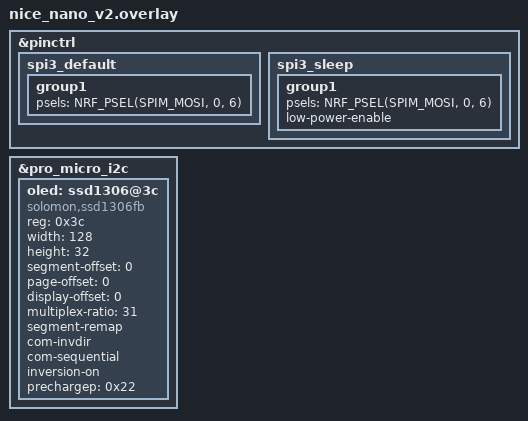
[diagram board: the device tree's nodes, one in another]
#include <dt-bindings/led/led.h>

&pinctrl {
    spi3_default: spi3_default {
        group1 {
            psels = <NRF_PSEL(SPIM_MOSI, 0, 6)>;
        };
    };

    spi3_sleep: spi3_sleep {
        group1 {
            psels = <NRF_PSEL(SPIM_MOSI, 0, 6)>;
            low-power-enable;
        };
    };
};

// OLED display
&pro_micro_i2c {
    status = "okay";

    oled: ssd1306@3c {
        compatible = "solomon,ssd1306fb";
        reg = <0x3c>;
        width = <128>;
        height = <32>;
        segment-offset = <0>;
        page-offset = <0>;
        display-offset = <0>;
        multiplex-ratio = <31>;
        segment-remap;
        com-invdir;
        com-sequential;
        inversion-on;
        prechargep = <0x22>;
    };
};

// vim: filetype=dts fdm=marker:
